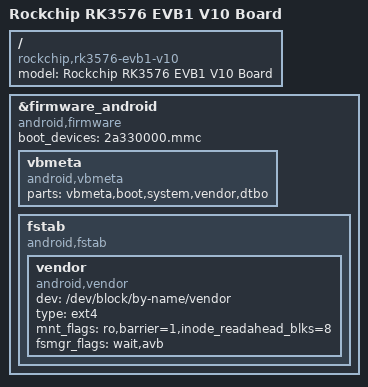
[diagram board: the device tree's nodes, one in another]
// SPDX-License-Identifier: (GPL-2.0+ OR MIT)
/*
 * Copyright (c) 2024 Rockchip Electronics Co., Ltd.
 *
 */

/dts-v1/;

#include "rk3576.dtsi"
#include "rk3576-evb1.dtsi"
#include "rk3576-virtual-poweroff.dtsi"
#include "rk3576-evb1-cam-dcphy0.dtsi"
#include "rk3576-android9.dtsi"

/ {
	model = "Rockchip RK3576 EVB1 V10 Board";
	compatible = "rockchip,rk3576-evb1-v10", "rockchip,rk3576", "rockchip,Android9";
};

&firmware_android {
	compatible = "android,firmware";
	boot_devices = "2a330000.mmc";
	vbmeta {
		compatible = "android,vbmeta";
		parts = "vbmeta,boot,system,vendor,dtbo";
	};
	fstab {
		compatible = "android,fstab";
		vendor {
			compatible = "android,vendor";
			dev = "/dev/block/by-name/vendor";
			type = "ext4";
			mnt_flags = "ro,barrier=1,inode_readahead_blks=8";
			fsmgr_flags = "wait,avb";
		};
	};
};

